# NUC1261AE_v1 register map
File version: 1.0
Registers are 32-bit, read-write, reset 0x0 unless marked. A register's access mark holds for its fields unless they carry their own. Offsets are from the block's base; [hi:lo] are bit positions.

## WDT — WDT Register Map
Base 0x40004000
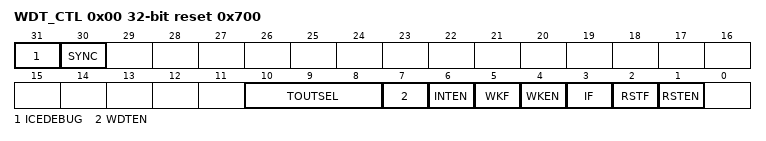
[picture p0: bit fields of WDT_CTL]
0x00 WDT_CTL reset 0x700 — WDT Control Register
  [31] ICEDEBUG — ICE Debug Mode Acknowledge Disable Bit (Write Protect). WDT up counter will keep going no matter CPU is held by ICE or not. Note: This bit is write protected. Refer to the SYS_REGLCTL register.
    0=ICE debug mode acknowledgement affects WDT counting; 1=ICE debug mode acknowledgement Disabled
  [30] SYNC ro — WDT Enable Control SYNC Flag Indicator (Read Only). If user execute enable/disable WDTEN (WDT_CTL[7]), this flag can be indicated enable/disable WDTEN function is completed or not. Note: Perform enable or disable WDTEN bit needs 2 * WDT_CLK period to become active.
    0=Set WDTEN bit is completed; 1=Set WDTEN bit is synchronizing and not become active yet
  [10:8] TOUTSEL — WDT Time-out Interval Selection (Write Protect). These three bits select the time-out interval period after WDT starts counting. Note: This bit is write protected. Refer to the SYS_REGLCTL register.
    0=24 * WDT_CLK; 1=26 * WDT_CLK; 2=28 * WDT_CLK; 3=210 * WDT_CLK; 4=212 * WDT_CLK; 5=214 * WDT_CLK; 6=216 * WDT_CLK; 7=218 * WDT_CLK
  [7] WDTEN — WDT Enable Bit (Write Protect). Note1: This bit is write protected. Refer to the SYS_REGLCTL register. Note2: Perform enable or disable WDTEN bit needs 2 * WDT_CLK period to become active, user can read SYNC (WDT_CTL[30]) to check enabe/disable command is completed or not. Note3: If CWDTEN[2:0] (combined with Config0[31] and Config0[4:3]) bits is not configure to 0x111, this bit is forced as 1 and user cannot change this bit to 0.Reserved.
    0=Set WDT counter stop, and internal up counter value will be reset also; 1=Set WDT counter start
  [6] INTEN — WDT Time-out Interrupt Enable Bit (Write Protect). If this bit is enabled, when WDT time-out event occurs, the IF (WDT_CTL[3]) will be set to 1 and WDT time-out interrupt signal is generated and inform to CPU. Note: This bit is write protected. Refer to the SYS_REGLCTL register.
    0=WDT time-out interrupt Disabled; 1=WDT time-out interrupt Enabled
  [5] WKF — WDT Time-out Wake-up Flag (Write Protect). This bit indicates the WDT time-out event has triggered chip wake-up or not. Note: This bit is cleared by writing 1 to it.
    0=WDT does not cause chip wake-up; 1=Chip wake-up from Idle or Power-down mode when WDT time-out interrupt signal is generated
  [4] WKEN — WDT Time-out Wake-up Function Control (Write Protect). If this bit is set to 1, while WDT time-out interrupt flag IF (WDT_CTL[3]) is generated and interrupt enable bit INTEN (WDT_CTL[6]) is enabled, the WDT time-out interrupt signal will generate a event to trigger CPU wake-up. Note1: This bit is write protected. Refer to the SYS_REGLCTL register. Note2: Chip can be woken-up while WDT time-out interrupt signal generated only if WDT clock source is selected to LIRC (10 kHz) or LXT (32 kHz).
    0=Trigger wake-up event function Disabled if WDT time-out interrupt signal generated; 1=Trigger wake-up event function Enabled if WDT time-out interrupt signal generated
  [3] IF — WDT Time-out Interrupt Flag. This bit will set to 1 while WDT up counter value reaches the selected WDT time-out interval. Note: This bit is cleared by writing 1 to it.
    0=WDT time-out interrupt event did not occur; 1=WDT time-out interrupt event occurred
  [2] RSTF — WDT Time-out Reset Flag. This bit indicates the system has been reset by WDT time-out reset system event or not. Note: This bit is cleared by writing 1 to it.
    0=WDT time-out reset system event did not occur; 1=WDT time-out reset system event has been occurred
  [1] RSTEN — WDT Time-out Reset Enable Bit (Write Protect). Setting this bit will enable the WDT time-out reset system function If the WDT up counter value has not been cleared after the specific WDT reset delay period expires. Note: This bit is write protected. Refer to the SYS_REGLCTL register.
    0=WDT time-out reset system function Disabled; 1=WDT time-out reset system function Enabled
0x04 WDT_ALTCTL — WDT Alternative Control Register
  [1:0] RSTDSEL — WDT Reset Delay Period Selection (Write Protect). When WDT time-out event happened, user has a time named WDT Reset Delay Period to execute WDT counter reset to prevent WDT time-out reset system occurred. User can select a suitable setting of RSTDSEL for application program. Note1: This bit is write protected. Refer to the SYS_REGLCTL register. Note2: This register will be reset to 0 if WDT time-out reset system event occurred.
    0=WDT Reset Delay Period is 1026 * WDT_CLK; 1=WDT Reset Delay Period is 130 * WDT_CLK; 2=WDT Reset Delay Period is 18 * WDT_CLK; 3=WDT Reset Delay Period is 3 * WDT_CLK
0x08 WDT_RSTCNT wo — WDT Reset Counter Register
  [31:0] RSTCNT — WDT Reset Counter Register. Writing 0x00005AA5 to this field will reset the internal 18-bit WDT up counter value to 0. Note: Perform RSTCNT to reset counter needs 2 * WDT_CLK period to become active.Reserved.
